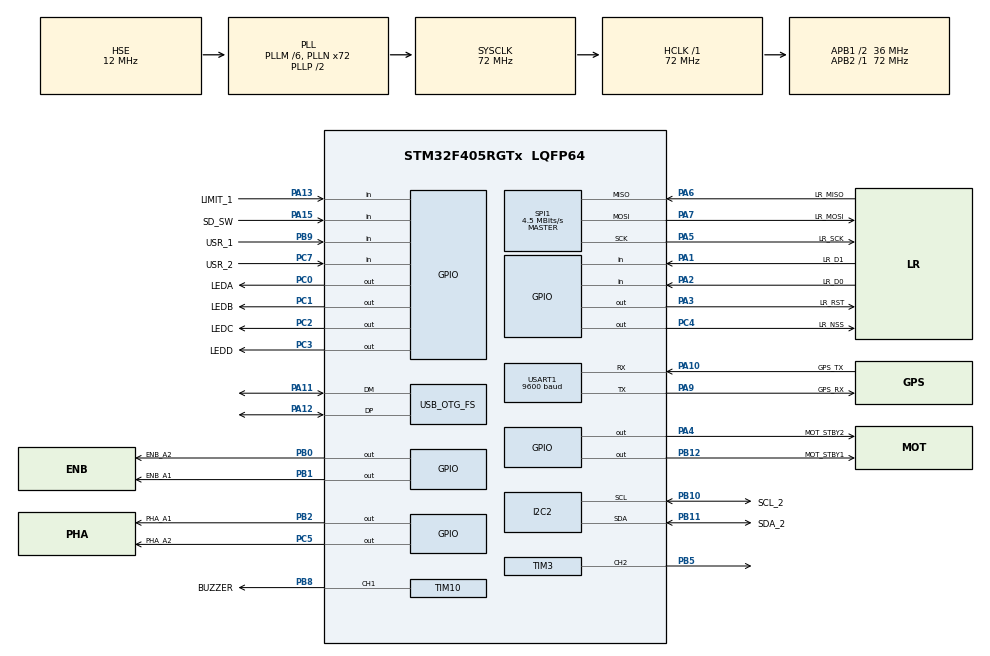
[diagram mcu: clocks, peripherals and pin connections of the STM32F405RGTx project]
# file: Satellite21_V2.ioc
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I2C2.I2C_Mode=I2C_Fast
Mcu.Family=STM32F4
Mcu.Name=STM32F405RGTx
Mcu.Package=LQFP64
NVIC.OTG_FS_IRQn=true\:0\:0\:false\:false\:true\:false\:true
NVIC.PriorityGroup=NVIC_PRIORITYGROUP_4
NVIC.USART1_IRQn=true\:0\:0\:false\:false\:true\:true\:true
PA1.GPIO_Label=LR_D1
PA1.GPIO_PuPd=GPIO_PULLDOWN
PA1.Signal=GPIO_Input
PA10.GPIO_Label=GPS_TX
PA10.GPIO_PuPd=GPIO_PULLUP
PA10.Mode=Asynchronous
PA10.Signal=USART1_RX
PA11.Mode=Device_Only
PA11.Signal=USB_OTG_FS_DM
PA12.Mode=Device_Only
PA12.Signal=USB_OTG_FS_DP
PA13.GPIO_Label=LIMIT_1
PA13.GPIO_PuPd=GPIO_PULLDOWN
PA13.Signal=GPIO_Input
PA15.GPIO_Label=SD_SW
PA15.Signal=GPIO_Input
PA2.GPIO_Label=LR_D0
PA2.GPIO_PuPd=GPIO_PULLDOWN
PA2.Signal=GPIO_Input
PA3.GPIO_Label=LR_RST
PA3.GPIO_PuPd=GPIO_PULLDOWN
PA3.Signal=GPIO_Output
PA4.GPIO_Label=MOT_STBY2
PA4.Signal=GPIO_Output
PA5.GPIO_Label=LR_SCK
PA5.Mode=Full_Duplex_Master
PA5.Signal=SPI1_SCK
PA6.GPIO_Label=LR_MISO
PA6.Mode=Full_Duplex_Master
PA6.Signal=SPI1_MISO
PA7.GPIO_Label=LR_MOSI
PA7.Mode=Full_Duplex_Master
PA7.Signal=SPI1_MOSI
PA9.GPIO_Label=GPS_RX
PA9.GPIO_PuPd=GPIO_PULLUP
PA9.Mode=Asynchronous
PA9.Signal=USART1_TX
PB0.GPIO_Label=ENB_A2
PB0.GPIO_PuPd=GPIO_PULLDOWN
PB0.Signal=GPIO_Output
PB1.GPIO_Label=ENB_A1
PB1.GPIO_PuPd=GPIO_PULLDOWN
PB1.Signal=GPIO_Output
PB10.GPIO_Label=SCL_2
PB10.Mode=I2C
PB10.Signal=I2C2_SCL
PB11.GPIO_Label=SDA_2
PB11.Mode=I2C
PB11.Signal=I2C2_SDA
PB12.GPIO_Label=MOT_STBY1
PB12.Signal=GPIO_Output
PB2.GPIO_Label=PHA_A1
PB2.GPIO_PuPd=GPIO_PULLDOWN
PB2.Signal=GPIO_Output
PB5.Signal=S_TIM3_CH2
PB8.GPIO_Label=BUZZER
PB8.Signal=S_TIM10_CH1
PB9.GPIO_Label=USR_1
PB9.GPIO_PuPd=GPIO_PULLDOWN
PB9.Signal=GPIO_Input
PC0.GPIO_Label=LEDA
PC0.PinState=GPIO_PIN_SET
PC0.Signal=GPIO_Output
PC1.GPIO_Label=LEDB
PC1.Signal=GPIO_Output
PC14-OSC32_IN.Mode=LSE-External-Oscillator
PC14-OSC32_IN.Signal=RCC_OSC32_IN
PC15-OSC32_OUT.Mode=LSE-External-Oscillator
PC15-OSC32_OUT.Signal=RCC_OSC32_OUT
PC2.GPIO_Label=LEDC
PC2.Signal=GPIO_Output
PC3.GPIO_Label=LEDD
PC3.Signal=GPIO_Output
PC4.GPIO_Label=LR_NSS
PC4.GPIO_PuPd=GPIO_PULLDOWN
PC4.Signal=GPIO_Output
PC5.GPIO_Label=PHA_A2
PC5.GPIO_PuPd=GPIO_PULLDOWN
PC5.Signal=GPIO_Output
PC7.GPIO_Label=USR_2
PC7.GPIO_PuPd=GPIO_PULLDOWN
PC7.Signal=GPIO_Input
PH0-OSC_IN.Mode=HSE-External-Oscillator
PH0-OSC_IN.Signal=RCC_OSC_IN
PH1-OSC_OUT.Mode=HSE-External-Oscillator
PH1-OSC_OUT.Signal=RCC_OSC_OUT
ProjectManager.HeapSize=0x200
ProjectManager.StackSize=0x400
ProjectManager.TargetToolchain=Makefile
RCC.48MHZClocksFreq_Value=48000000
RCC.AHBFreq_Value=72000000
RCC.APB1CLKDivider=RCC_HCLK_DIV2
RCC.APB1Freq_Value=36000000
RCC.APB1TimFreq_Value=72000000
RCC.APB2Freq_Value=72000000
RCC.APB2TimFreq_Value=72000000
RCC.CortexFreq_Value=72000000
RCC.HCLKFreq_Value=72000000
RCC.HSE_VALUE=12000000
RCC.HSI_VALUE=16000000
RCC.LSE_Timout=5000
RCC.PLLM=6
RCC.PLLN=72
RCC.PLLQ=3
RCC.RCC_MCO1Source=RCC_MCO1SOURCE_HSE
RCC.RCC_MCODiv2=RCC_MCODIV_3
RCC.RCC_RTC_Clock_Source=RCC_RTCCLKSOURCE_LSE
RCC.RCC_RTC_Clock_SourceVirtual=RCC_RTCCLKSOURCE_LSE
RCC.SYSCLKFreq_VALUE=72000000
RCC.SYSCLKSource=RCC_SYSCLKSOURCE_PLLCLK
RCC.VCOOutputFreq_Value=144000000
SH.S_TIM10_CH1.0=TIM10_CH1,PWM Generation1 CH1
SH.S_TIM3_CH2.0=TIM3_CH2,PWM Generation2 CH2
SPI1.BaudRatePrescaler=SPI_BAUDRATEPRESCALER_16
SPI1.CalculateBaudRate=4.5 MBits/s
SPI1.Direction=SPI_DIRECTION_2LINES
SPI1.Mode=SPI_MODE_MASTER
SPI1.VirtualType=VM_MASTER
TIM10.AutoReloadPreload=TIM_AUTORELOAD_PRELOAD_ENABLE
TIM10.Channel=TIM_CHANNEL_1
TIM10.OCFastMode_PWM=TIM_OCFAST_ENABLE
TIM10.Period=19999
TIM10.Pulse=9999
TIM2.Prescaler=71
TIM3.Channel-PWM\ Generation2\ CH2=TIM_CHANNEL_2
TIM3.Period=1023
TIM3.Prescaler=1
USART1.BaudRate=9600
USART1.VirtualMode=VM_ASYNC
USB_DEVICE.CLASS_NAME_FS=CDC
USB_DEVICE.VirtualMode-CDC_FS=Cdc
USB_DEVICE.VirtualModeFS=Cdc_FS
USB_OTG_FS.VirtualMode=Device_Only
VP_RTC_VS_RTC_Activate.Mode=RTC_Enabled
VP_TIM10_VS_ClockSourceINT.Mode=Enable_Timer
VP_TIM2_VS_ClockSourceINT.Mode=Internal
VP_TIM3_VS_ClockSourceINT.Mode=Internal
VP_USB_DEVICE_VS_USB_DEVICE_CDC_FS.Mode=CDC_FS
board=custom

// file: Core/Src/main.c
/* USER CODE BEGIN Header */
/**
  ******************************************************************************
  * @file           : main.c
  * @brief          : Main program body
  ******************************************************************************
  * @attention
  *
  * <h2><center>&copy; Copyright (c) 2021 STMicroelectronics.
  * All rights reserved.</center></h2>
  *
  * This software component is licensed by ST under BSD 3-Clause license,
  * the "License"; You may not use this file except in compliance with the
  * License. You may obtain a copy of the License at:
  *                        opensource.org/licenses/BSD-3-Clause
  *
  ******************************************************************************
  */
/* USER CODE END Header */
#include "main.h"
#include "i2c.h"
#include "rtc.h"
#include "spi.h"
#include "tim.h"
#include "usart.h"
#include "usb_device.h"
#include "gpio.h"

/* USER CODE BEGIN Includes */

#include "run.h"

/* USER CODE END Includes */

void SystemClock_Config(void);

int main(void)
{

  /* MCU Configuration--------------------------------------------------------*/

  /* Reset of all peripherals, Initializes the Flash interface and the Systick. */
  HAL_Init();

  /* Configure the system clock */
  SystemClock_Config();

  /* Initialize all configured peripherals */
  MX_GPIO_Init();
  MX_SPI1_Init();
  MX_TIM3_Init();
  MX_TIM2_Init();
  MX_I2C2_Init();
  MX_USART1_UART_Init();
  MX_USB_DEVICE_Init();
  MX_TIM10_Init();
  MX_RTC_Init();
  /* USER CODE BEGIN 2 */

  HAL_TIM_PWM_Start(&htim3,TIM_CHANNEL_2);
  HAL_TIM_Base_Start(&htim2);
  setup();

  /* USER CODE END 2 */

  /* Infinite loop */
  /* USER CODE BEGIN WHILE */
  while (1)
  {

    loop();
    /* USER CODE END WHILE */

  }
}

void SystemClock_Config(void)
{
  RCC_OscInitTypeDef RCC_OscInitStruct = {0};
  RCC_ClkInitTypeDef RCC_ClkInitStruct = {0};
  RCC_PeriphCLKInitTypeDef PeriphClkInitStruct = {0};

  /** Configure the main internal regulator output voltage
  */
  __HAL_RCC_PWR_CLK_ENABLE();
  __HAL_PWR_VOLTAGESCALING_CONFIG(PWR_REGULATOR_VOLTAGE_SCALE1);
  /** Initializes the RCC Oscillators according to the specified parameters
  * in the RCC_OscInitTypeDef structure.
  */
  RCC_OscInitStruct.OscillatorType = RCC_OSCILLATORTYPE_HSE|RCC_OSCILLATORTYPE_LSE;
  RCC_OscInitStruct.HSEState = RCC_HSE_ON;
  RCC_OscInitStruct.LSEState = RCC_LSE_ON;
  RCC_OscInitStruct.PLL.PLLState = RCC_PLL_ON;
  RCC_OscInitStruct.PLL.PLLSource = RCC_PLLSOURCE_HSE;
  RCC_OscInitStruct.PLL.PLLM = 6;
  RCC_OscInitStruct.PLL.PLLN = 72;
  RCC_OscInitStruct.PLL.PLLP = RCC_PLLP_DIV2;
  RCC_OscInitStruct.PLL.PLLQ = 3;
  if (HAL_RCC_OscConfig(&RCC_OscInitStruct) != HAL_OK)
  {
    Error_Handler();
  }
  /** Initializes the CPU, AHB and APB buses clocks
  */
  RCC_ClkInitStruct.ClockType = RCC_CLOCKTYPE_HCLK|RCC_CLOCKTYPE_SYSCLK
                              |RCC_CLOCKTYPE_PCLK1|RCC_CLOCKTYPE_PCLK2;
  RCC_ClkInitStruct.SYSCLKSource = RCC_SYSCLKSOURCE_PLLCLK;
  RCC_ClkInitStruct.AHBCLKDivider = RCC_SYSCLK_DIV1;
  RCC_ClkInitStruct.APB1CLKDivider = RCC_HCLK_DIV2;
  RCC_ClkInitStruct.APB2CLKDivider = RCC_HCLK_DIV1;

  if (HAL_RCC_ClockConfig(&RCC_ClkInitStruct, FLASH_LATENCY_2) != HAL_OK)
  {
    Error_Handler();
  }
  PeriphClkInitStruct.PeriphClockSelection = RCC_PERIPHCLK_RTC;
  PeriphClkInitStruct.RTCClockSelection = RCC_RTCCLKSOURCE_LSE;
  if (HAL_RCCEx_PeriphCLKConfig(&PeriphClkInitStruct) != HAL_OK)
  {
    Error_Handler();
  }
}

/* USER CODE BEGIN 4 */

I2C_HandleTypeDef* I2C2_Handler (void) { return &hi2c2; }
SPI_HandleTypeDef* Get_SPI1_Instance(void) { return &hspi1; }
TIM_HandleTypeDef* Get_TIM10_Instance(void) { return &htim10; }
RTC_HandleTypeDef* Get_RTC_Instance(void) { return &hrtc; }
UART_HandleTypeDef* Get_UART1_Instance(void) { return &huart1; }

/* USER CODE END 4 */

void Error_Handler(void)
{
  __disable_irq();
  while (1)
  {
  }
}

/************************ (C) COPYRIGHT STMicroelectronics *****END OF FILE****/
